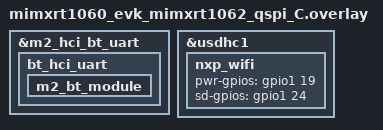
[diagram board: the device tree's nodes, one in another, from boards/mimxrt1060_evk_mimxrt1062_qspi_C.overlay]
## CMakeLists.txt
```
# SPDX-License-Identifier: Apache-2.0

cmake_minimum_required(VERSION 3.20.0)
find_package(Zephyr REQUIRED HINTS $ENV{ZEPHYR_BASE})
project(coex_shell)

file(GLOB app_sources src/*.c)
target_sources(app PRIVATE ${app_sources})
```

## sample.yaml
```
common:
  harness: net
  tags:
    - net
    - bluetooth
    - wifi
    - openthread
    - coex
  depends_on: openthread
sample:
  description: Test Bluetooth, Wi-Fi, and OpenThread coexistence shell functionality
  name: Wireless coexistence shell
tests:
  sample.net.wireless.coex.shell.nxp:
    build_only: true
    harness: bluetooth
    platform_allow:
      - frdm_rw612
      - rd_rw612_bga
      - mimxrt1060_evk@C/mimxrt1062/qspi
    integration_platforms:
      - rd_rw612_bga
    extra_args: >
      board:mimxrt1060_evk@C/mimxrt1062/qspi:SHIELD=nxp_m2_2ll_wifi_bt
      board:frdm_rw612:CONFIG_NXP_MONOLITHIC_WIFI=n
      board:frdm_rw612:CONFIG_NXP_MONOLITHIC_NBU=n
      board:rd_rw612_bga:CONFIG_NXP_MONOLITHIC_WIFI=n
      board:rd_rw612_bga:CONFIG_NXP_MONOLITHIC_NBU=n
```

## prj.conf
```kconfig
CONFIG_LOG=y
CONFIG_LOG_RUNTIME_FILTERING=y
CONFIG_LOG_MODE_IMMEDIATE=y
CONFIG_SYSTEM_WORKQUEUE_STACK_SIZE=2048
CONFIG_REQUIRES_FULL_LIBC=y
CONFIG_SHELL=y
```

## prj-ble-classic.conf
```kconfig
# Bluetooth Classic (BR/EDR) shell configuration

CONFIG_BT=y
CONFIG_BT_CLASSIC=y
CONFIG_BT_RFCOMM=y
CONFIG_BT_A2DP=y
CONFIG_BT_A2DP_SOURCE=y
CONFIG_BT_A2DP_SINK=y
CONFIG_BT_SHELL=y
CONFIG_BT_CENTRAL=y
CONFIG_BT_PERIPHERAL=y
CONFIG_BT_PRIVACY=y
CONFIG_BT_SMP=y
CONFIG_BT_ATT_PREPARE_COUNT=2
CONFIG_BT_GATT_CLIENT=y
CONFIG_BT_RX_STACK_SIZE=2048
CONFIG_BT_L2CAP_DYNAMIC_CHANNEL=y
CONFIG_BT_DEVICE_NAME="BT Coex Shell"
CONFIG_BT_L2CAP_RET=y
CONFIG_BT_L2CAP_FC=y
CONFIG_BT_L2CAP_ENH_RET=y
CONFIG_BT_L2CAP_STREAM=y
CONFIG_BT_L2CAP_FCS=y
CONFIG_BT_L2CAP_EXT_WIN_SIZE=y
CONFIG_BT_L2CAP_MAX_WINDOW_SIZE=5
CONFIG_BT_L2CAP_CONNLESS=y

CONFIG_BT_HFP_HF=y
CONFIG_BT_HFP_AG=y

CONFIG_BT_GOEP=y
CONFIG_BT_OEBX_RSP_CODE_TO_STR=y

CONFIG_BT_AVCTP=y
CONFIG_BT_AVRCP=y
CONFIG_BT_AVRCP_TARGET=y
CONFIG_BT_AVRCP_CONTROLLER=y
CONFIG_BT_AVRCP_BROWSING=y

CONFIG_BT_AVRCP_TG_COVER_ART=y
CONFIG_BT_AVRCP_CT_COVER_ART_GET_IMAGE_PROPERTIES=y
CONFIG_BT_AVRCP_CT_COVER_ART_GET_IMAGE=y
CONFIG_BT_AVRCP_CT_COVER_ART_GET_LINKED_THUMBNAIL=y

CONFIG_BT_BIP=y
```

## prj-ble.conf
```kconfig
# Bluetooth LE shell configuration

CONFIG_BT=y
CONFIG_BT_CENTRAL=y
CONFIG_BT_PERIPHERAL=y
CONFIG_BT_PRIVACY=y
CONFIG_BT_SMP=y
CONFIG_BT_PASSKEY_KEYPRESS=y
CONFIG_BT_APP_PASSKEY=y
CONFIG_BT_ATT_PREPARE_COUNT=2
CONFIG_BT_GATT_CLIENT=y
CONFIG_BT_L2CAP_DYNAMIC_CHANNEL=y
CONFIG_BT_SHELL=y
CONFIG_BT_DEVICE_NAME="BT Coex Shell"
CONFIG_BT_DEVICE_NAME_DYNAMIC=y
CONFIG_BT_L2CAP_TX_BUF_COUNT=4
CONFIG_BT_ID_MAX=2
CONFIG_BT_EATT=y
CONFIG_BT_L2CAP_ECRED=y
CONFIG_BT_GATT_DYNAMIC_DB=y
CONFIG_BT_GATT_NOTIFY_MULTIPLE=y
CONFIG_BT_FILTER_ACCEPT_LIST=y
CONFIG_BT_REMOTE_INFO=y
CONFIG_BT_REMOTE_VERSION=y
CONFIG_BT_GATT_AUTO_DISCOVER_CCC=y

CONFIG_BT_SETTINGS=y
CONFIG_FLASH=y
CONFIG_FLASH_MAP=y
CONFIG_NVS=y
CONFIG_SETTINGS=y

CONFIG_BT_EXT_ADV=y
CONFIG_BT_EXT_ADV_LEGACY_SUPPORT=y
CONFIG_BT_PER_ADV=y
CONFIG_BT_PER_ADV_SYNC=y

CONFIG_BT_USER_DATA_LEN_UPDATE=y
CONFIG_BT_AUTO_DATA_LEN_UPDATE=y

CONFIG_BT_EAD=y
CONFIG_BT_USER_PHY_UPDATE=y
```

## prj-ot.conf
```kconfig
# Increased main stack size required for initialization
CONFIG_MAIN_STACK_SIZE=4096

# Enable Networking and OpenThread stack
CONFIG_NETWORKING=y
CONFIG_NET_L2_OPENTHREAD=y

# Use NVS as settings backend
CONFIG_NVS=y

# Logging
CONFIG_LOG=y
CONFIG_NET_LOG=y

# Networking and OpenThread shells
CONFIG_SHELL=y
CONFIG_NET_SHELL=y
CONFIG_OPENTHREAD_SHELL=y

# CPP library
CONFIG_CPP=y

# Flash
CONFIG_FLASH=y
CONFIG_FLASH_MAP=y

# OpenThread features
CONFIG_OPENTHREAD_MANUAL_START=y
CONFIG_OPENTHREAD_THREAD_VERSION_1_4=y
CONFIG_OPENTHREAD_DHCP6_SERVER=y
CONFIG_OPENTHREAD_COMMISSIONER=y
CONFIG_OPENTHREAD_BORDER_AGENT=y
CONFIG_OPENTHREAD_BORDER_ROUTER=y
CONFIG_OPENTHREAD_UDP_FORWARD=y
CONFIG_OPENTHREAD_ENABLE_SERVICE=y
CONFIG_OPENTHREAD_EXTERNAL_HEAP=y
CONFIG_OPENTHREAD_PING_SENDER=y
CONFIG_OPENTHREAD_SLAAC=y
CONFIG_OPENTHREAD_SETTINGS_RAM=y
CONFIG_OPENTHREAD_NUM_MESSAGE_BUFFERS=256
CONFIG_OPENTHREAD_COAP=y
CONFIG_OPENTHREAD_JOINER=y
CONFIG_OPENTHREAD_DHCP6_CLIENT=y
CONFIG_OPENTHREAD_LINK_METRICS_INITIATOR=y
CONFIG_OPENTHREAD_LINK_METRICS_SUBJECT=y
CONFIG_OPENTHREAD_DUA=y
CONFIG_OPENTHREAD_MLR=y
CONFIG_OPENTHREAD_ECDSA=y
CONFIG_OPENTHREAD_DNS_CLIENT=y
CONFIG_OPENTHREAD_DNSSD_SERVER=y
CONFIG_OPENTHREAD_SRP_CLIENT=y
CONFIG_OPENTHREAD_SRP_SERVER=y
CONFIG_OPENTHREAD_MAC_FILTER=y
CONFIG_OPENTHREAD_IP6_FRAGM=y
```

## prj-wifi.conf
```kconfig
# Wi-Fi protocol configuration
CONFIG_EARLY_CONSOLE=y

CONFIG_NETWORKING=y
CONFIG_TEST_RANDOM_GENERATOR=y

CONFIG_MAIN_STACK_SIZE=5200
CONFIG_SHELL_STACK_SIZE=5200
CONFIG_NET_TX_STACK_SIZE=2048
CONFIG_NET_RX_STACK_SIZE=2048

CONFIG_NET_PKT_RX_COUNT=10
CONFIG_NET_PKT_TX_COUNT=10
CONFIG_NET_BUF_RX_COUNT=20
CONFIG_NET_BUF_TX_COUNT=20
CONFIG_NET_MAX_CONTEXTS=10
CONFIG_NET_DHCPV4=y

CONFIG_NET_IPV4=y
CONFIG_NET_IPV6=n

CONFIG_NET_TCP=y

CONFIG_NET_LOG=y
CONFIG_INIT_STACKS=y

CONFIG_NET_SHELL=y

CONFIG_NET_STATISTICS=y
CONFIG_NET_STATISTICS_PERIODIC_OUTPUT=n

CONFIG_WIFI=y
CONFIG_WIFI_LOG_LEVEL_ERR=y
CONFIG_NET_L2_WIFI_SHELL=y
# printing of scan results puts pressure on queues in new locking
# design in net_mgmt. So, use a higher timeout for a crowded
# environment.
CONFIG_NET_MGMT_EVENT_QUEUE_TIMEOUT=5000
CONFIG_NET_MGMT_EVENT_QUEUE_SIZE=20
```

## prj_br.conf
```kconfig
CONFIG_BT=y
CONFIG_BT_CLASSIC=y
CONFIG_BT_RFCOMM=y
CONFIG_BT_A2DP=y
CONFIG_BT_A2DP_SOURCE=y
CONFIG_BT_A2DP_SINK=y
CONFIG_BT_SHELL=y
CONFIG_LOG=y
CONFIG_BT_CENTRAL=y
CONFIG_BT_PERIPHERAL=y
CONFIG_BT_PRIVACY=y
CONFIG_BT_SMP=y
CONFIG_BT_ATT_PREPARE_COUNT=2
CONFIG_BT_GATT_CLIENT=y
CONFIG_BT_RX_STACK_SIZE=2048
CONFIG_BT_L2CAP_DYNAMIC_CHANNEL=y
CONFIG_BT_DEVICE_NAME="BT Coex Shell"
CONFIG_BT_L2CAP_RET=y
CONFIG_BT_L2CAP_FC=y
CONFIG_BT_L2CAP_ENH_RET=y
CONFIG_BT_L2CAP_STREAM=y
CONFIG_BT_L2CAP_FCS=y
CONFIG_BT_L2CAP_EXT_WIN_SIZE=y
CONFIG_BT_L2CAP_MAX_WINDOW_SIZE=5
CONFIG_BT_L2CAP_CONNLESS=y

CONFIG_BT_HFP_HF=y
CONFIG_BT_HFP_AG=y

CONFIG_BT_GOEP=y
CONFIG_BT_OEBX_RSP_CODE_TO_STR=y

CONFIG_BT_AVCTP=y
CONFIG_BT_AVRCP=y
CONFIG_BT_AVRCP_TARGET=y
CONFIG_BT_AVRCP_CONTROLLER=y
CONFIG_BT_AVRCP_BROWSING=y

CONFIG_BT_AVRCP_TG_COVER_ART=y
CONFIG_BT_AVRCP_CT_COVER_ART_GET_IMAGE_PROPERTIES=y
CONFIG_BT_AVRCP_CT_COVER_ART_GET_IMAGE=y
CONFIG_BT_AVRCP_CT_COVER_ART_GET_LINKED_THUMBNAIL=y

CONFIG_BT_BIP=y
```

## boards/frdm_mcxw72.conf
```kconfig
# Copyright 2026 NXP
# SPDX-License-Identifier: Apache-2.0

# OS
CONFIG_HEAP_MEM_POOL_SIZE=4096

#shell
CONFIG_SHELL_STACK_SIZE=4096

# Enabling the IEEE802154 CSL endpoint and OpenThread CSL receiver
CONFIG_IEEE802154_CSL_ENDPOINT=y
CONFIG_OPENTHREAD_CSL_RECEIVER=y

# Secure storage
CONFIG_SECURE_STORAGE_ITS_TRANSFORM_AEAD_KEY_PROVIDER_ENTRY_UID_HASH=y
```

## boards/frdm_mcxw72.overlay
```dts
/*
 * Copyright 2026 NXP
 * SPDX-License-Identifier: Apache-2.0
 */

&ieee802154_eui64_ifr0 {
	status = "okay";
};
```

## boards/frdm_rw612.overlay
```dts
/*
 * Copyright 2026 NXP
 *
 * SPDX-License-Identifier: Apache-2.0
 */

/ {
	chosen {
		zephyr,uart-pipe = &flexcomm0;
	};
};

&flexcomm0 {
	status = "okay";
};

&standby {
	status = "okay";
};
```

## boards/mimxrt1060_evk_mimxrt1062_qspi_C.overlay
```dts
/*
 * Copyright 2026 NXP
 *
 * SPDX-License-Identifier: Apache-2.0
 */

&m2_hci_bt_uart {
	bt_hci_uart: bt_hci_uart {
		m2_bt_module: m2_bt_module {
			/delete-property/ sdio-reset-gpios;
			/delete-property/ w-disable-gpios;
		};
	};
};

&usdhc1 {
	nxp_wifi {
		pwr-gpios = <&gpio1 19 GPIO_ACTIVE_HIGH>;
		sd-gpios = <&gpio1 24 GPIO_ACTIVE_HIGH>;
	};
};
```

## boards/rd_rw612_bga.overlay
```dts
/*
 * Copyright 2026 NXP
 *
 * SPDX-License-Identifier: Apache-2.0
 */

/ {
	chosen {
		zephyr,uart-pipe = &flexcomm0;
	};
};

&flexcomm0 {
	compatible = "nxp,lpc-usart";
	status = "okay";
	current-speed = <115200>;
	pinctrl-0 = <&pinmux_flexcomm0_usart>;
	pinctrl-names = "default";
};

&standby {
	status = "okay";
};
```

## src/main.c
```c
/*
 * Copyright (c) 2026 NXP
 *
 * SPDX-License-Identifier: Apache-2.0
 */

#include <zephyr/kernel.h>
#include <zephyr/sys/printk.h>
#include <zephyr/drivers/uart.h>

int main(void)
{
#if DT_NODE_HAS_COMPAT(DT_CHOSEN(zephyr_shell_uart), zephyr_cdc_acm_uart)
	const struct device *dev;
	uint32_t dtr = 0;

	dev = DEVICE_DT_GET(DT_CHOSEN(zephyr_shell_uart));
	if (!device_is_ready(dev)) {
		return 0;
	}

	while (!dtr) {
		uart_line_ctrl_get(dev, UART_LINE_CTRL_DTR, &dtr);
		k_sleep(K_MSEC(100));
	}
#endif

	printk("Wireless Coexistence Shell Sample\n");
	printk("Type \"help\" for supported commands.\n");
	printk("Before any Bluetooth commands you must `bt init` to initialize the stack.\n");

	return 0;
}
```
